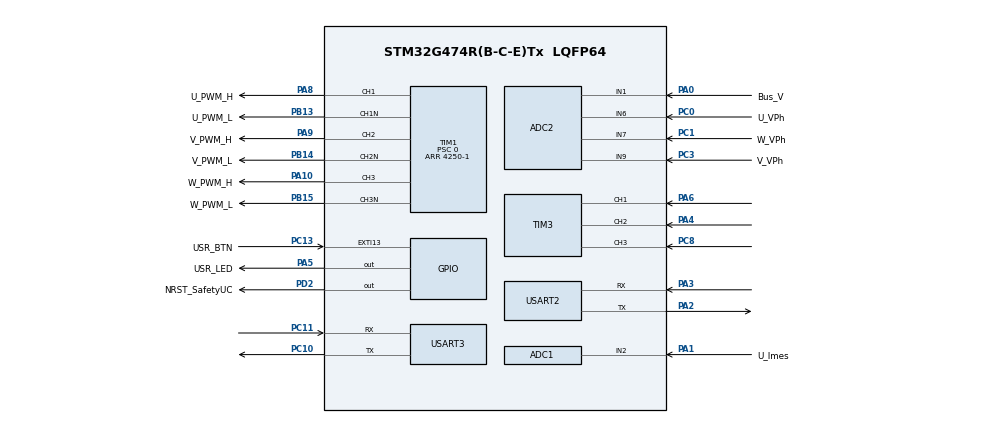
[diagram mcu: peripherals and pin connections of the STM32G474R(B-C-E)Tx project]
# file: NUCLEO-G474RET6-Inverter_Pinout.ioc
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ADC1.Channel-0\#ChannelRegularConversion=ADC_CHANNEL_2
ADC1.ContinuousConvMode=DISABLE
ADC1.DMAContinuousRequests=DISABLE
ADC1.ExternalTrigConv=ADC_EXTERNALTRIG_T1_TRGO
ADC1.NbrOfConversionFlag=1
ADC1.OffsetNumber-0\#ChannelRegularConversion=ADC_OFFSET_NONE
ADC1.OversamplingMode=DISABLE
ADC1.Rank-0\#ChannelRegularConversion=1
ADC1.SamplingTime-0\#ChannelRegularConversion=ADC_SAMPLETIME_2CYCLES_5
ADC1.master=1
ADC2.Channel-0\#ChannelRegularConversion=ADC_CHANNEL_6
ADC2.NbrOfConversionFlag=1
ADC2.OffsetNumber-0\#ChannelRegularConversion=ADC_OFFSET_NONE
ADC2.Rank-0\#ChannelRegularConversion=1
ADC2.SamplingTime-0\#ChannelRegularConversion=ADC_SAMPLETIME_2CYCLES_5
Dma.ADC1.0.Direction=DMA_PERIPH_TO_MEMORY
Dma.ADC1.0.EventEnable=DISABLE
Dma.ADC1.0.Instance=DMA1_Channel1
Dma.ADC1.0.MemDataAlignment=DMA_MDATAALIGN_HALFWORD
Dma.ADC1.0.MemInc=DMA_MINC_ENABLE
Dma.ADC1.0.Mode=DMA_NORMAL
Dma.ADC1.0.PeriphDataAlignment=DMA_PDATAALIGN_HALFWORD
Dma.ADC1.0.PeriphInc=DMA_PINC_DISABLE
Dma.ADC1.0.Polarity=HAL_DMAMUX_REQ_GEN_RISING
Dma.ADC1.0.Priority=DMA_PRIORITY_LOW
Dma.ADC1.0.RequestNumber=1
Dma.ADC1.0.SignalID=NONE
Dma.ADC1.0.SyncEnable=DISABLE
Dma.ADC1.0.SyncPolarity=HAL_DMAMUX_SYNC_NO_EVENT
Dma.ADC1.0.SyncRequestNumber=1
Dma.ADC1.0.SyncSignalID=NONE
Dma.Request0=ADC1
Mcu.Family=STM32G4
Mcu.Name=STM32G474R(B-C-E)Tx
Mcu.Package=LQFP64
NVIC.ADC1_2_IRQn=true\:0\:0\:false\:false\:true\:true\:true\:true
NVIC.DMA1_Channel1_IRQn=true\:0\:0\:false\:false\:true\:false\:true\:true
NVIC.EXTI15_10_IRQn=true\:0\:0\:false\:false\:true\:true\:true\:true
NVIC.PriorityGroup=NVIC_PRIORITYGROUP_4
NVIC.TIM1_TRG_COM_TIM17_IRQn=true\:0\:0\:false\:false\:true\:true\:true\:true
NVIC.TIM2_IRQn=true\:0\:0\:false\:false\:true\:true\:true\:true
NVIC.TIM6_DAC_IRQn=true\:15\:0\:false\:false\:true\:false\:true\:true
NVIC.TimeBase=TIM6_DAC_IRQn
NVIC.TimeBaseIP=TIM6
NVIC.USART2_IRQn=true\:0\:0\:false\:false\:true\:true\:true\:true
NVIC.USART3_IRQn=true\:0\:0\:false\:false\:true\:true\:true\:true
PA0.GPIO_Label=Bus_V
PA0.Mode=IN1-Single-Ended
PA0.Signal=ADC2_IN1
PA1.GPIO_Label=U_Imes
PA1.Mode=IN2-Single-Ended
PA1.Signal=ADC1_IN2
PA10.GPIO_Label=W_PWM_H
PA10.Signal=S_TIM1_CH3
PA13.GPIO_Label=T_SWDIO
PA13.Mode=Trace_Asynchronous_SW
PA13.Signal=SYS_JTMS-SWDIO
PA14.GPIO_Label=T_SWCLK
PA14.Mode=Trace_Asynchronous_SW
PA14.Signal=SYS_JTCK-SWCLK
PA2.Mode=Asynchronous
PA2.Signal=USART2_TX
PA3.Mode=Asynchronous
PA3.Signal=USART2_RX
PA4.Signal=S_TIM3_CH2
PA5.GPIO_Label=USR_LED
PA5.Signal=GPIO_Output
PA6.Signal=S_TIM3_CH1
PA8.GPIO_Label=U_PWM_H
PA8.Signal=S_TIM1_CH1
PA9.GPIO_Label=V_PWM_H
PA9.Signal=S_TIM1_CH2
PB0.Signal=ADC1_IN15
PB1.Signal=ADC1_IN12
PB13.GPIO_Label=U_PWM_L
PB13.Mode=PWM Generation1 CH1 CH1N
PB13.Signal=TIM1_CH1N
PB14.GPIO_Label=V_PWM_L
PB14.Mode=PWM Generation2 CH2 CH2N
PB14.Signal=TIM1_CH2N
PB15.GPIO_Label=W_PWM_L
PB15.Mode=PWM Generation3 CH3 CH3N
PB15.Signal=TIM1_CH3N
PB3.GPIO_Label=T_SWO
PB3.Mode=Trace_Asynchronous_SW
PB3.Signal=SYS_JTDO-SWO
PC0.GPIO_Label=U_VPh
PC0.Mode=IN6-Single-Ended
PC0.Signal=ADC2_IN6
PC1.GPIO_Label=W_VPh
PC1.Mode=IN7-Single-Ended
PC1.Signal=ADC2_IN7
PC10.Mode=Asynchronous
PC10.Signal=USART3_TX
PC11.Mode=Asynchronous
PC11.Signal=USART3_RX
PC13.GPIO_Label=USR_BTN
PC13.Signal=GPXTI13
PC14-OSC32_IN.Mode=LSE-External-Oscillator
PC14-OSC32_IN.Signal=RCC_OSC32_IN
PC15-OSC32_OUT.Mode=LSE-External-Oscillator
PC15-OSC32_OUT.Signal=RCC_OSC32_OUT
PC2.GPIO_Label=Bus_Imes
PC2.Signal=ADC1_IN8
PC3.GPIO_Label=V_VPh
PC3.Mode=IN9-Single-Ended
PC3.Signal=ADC2_IN9
PC8.Signal=S_TIM3_CH3
PD2.GPIO_Label=NRST_SafetyUC
PD2.Signal=GPIO_Output
PF0-OSC_IN.Mode=HSE-External-Oscillator
PF0-OSC_IN.Signal=RCC_OSC_IN
PF1-OSC_OUT.Mode=HSE-External-Oscillator
PF1-OSC_OUT.Signal=RCC_OSC_OUT
ProjectManager.HeapSize=0x200
ProjectManager.StackSize=0x400
ProjectManager.TargetToolchain=STM32CubeIDE
RCC.ADC12Freq_Value=170000000
RCC.ADC345Freq_Value=170000000
RCC.AHBFreq_Value=170000000
RCC.APB1Freq_Value=170000000
RCC.APB1TimFreq_Value=170000000
RCC.APB2Freq_Value=170000000
RCC.APB2TimFreq_Value=170000000
RCC.CortexFreq_Value=170000000
RCC.EXTERNAL_CLOCK_VALUE=12288000
RCC.HCLKFreq_Value=170000000
RCC.HSE_VALUE=24000000
RCC.HSI48_VALUE=48000000
RCC.HSI_VALUE=16000000
RCC.PLLM=RCC_PLLM_DIV6
RCC.PLLN=85
RCC.PLLSourceVirtual=RCC_PLLSOURCE_HSE
RCC.RTCClockSelection=RCC_RTCCLKSOURCE_LSE
RCC.SYSCLKFreq_VALUE=170000000
RCC.SYSCLKSource=RCC_SYSCLKSOURCE_PLLCLK
RCC.USBFreq_Value=170000000
RCC.VCOOutputFreq_Value=340000000
SH.S_TIM1_CH1.0=TIM1_CH1,PWM Generation1 CH1 CH1N
SH.S_TIM1_CH2.0=TIM1_CH2,PWM Generation2 CH2 CH2N
SH.S_TIM1_CH3.0=TIM1_CH3,PWM Generation3 CH3 CH3N
SH.S_TIM3_CH1.0=TIM3_CH1,Xored_Inputs_Hall_Sensor_Interface
SH.S_TIM3_CH2.0=TIM3_CH2,Xored_Inputs_Hall_Sensor_Interface
SH.S_TIM3_CH3.0=TIM3_CH3,Xored_Inputs_Hall_Sensor_Interface
TIM1.AutoReloadPreload=TIM_AUTORELOAD_PRELOAD_ENABLE
TIM1.Channel-PWM\ Generation1\ CH1\ CH1N=TIM_CHANNEL_1
TIM1.Channel-PWM\ Generation2\ CH2\ CH2N=TIM_CHANNEL_2
TIM1.Channel-PWM\ Generation3\ CH3\ CH3N=TIM_CHANNEL_3
TIM1.CounterMode=TIM_COUNTERMODE_CENTERALIGNED1
TIM1.DeadTime=34
TIM1.PeriodNoDither=4250-1
TIM1.Prescaler=0
TIM1.PulseNoDither_1=3000
TIM1.PulseNoDither_2=5000
TIM1.TIM_MasterOutputTrigger=TIM_TRGO_UPDATE
TIM1.TIM_MasterSlaveMode=TIM_MASTERSLAVEMODE_ENABLE
TIM2.PeriodNoDither=3333-1
TIM2.Prescaler=170-1
USART2.VirtualMode-Asynchronous=VM_ASYNC
USART3.VirtualMode-Asynchronous=VM_ASYNC
VP_SYS_VS_DBSignals.Mode=DisableDeadBatterySignals
VP_SYS_VS_tim6.Mode=TIM6
VP_TIM2_VS_ClockSourceINT.Mode=Internal
board=NUCLEO-G474RE

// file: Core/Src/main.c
/* USER CODE BEGIN Header */
/**
 ******************************************************************************
 * @file           : main.c
 * @brief          : Main program body
 ******************************************************************************
 * @attention
 *
 * Copyright (c) 2023 STMicroelectronics.
 * All rights reserved.
 *
 * This software is licensed under terms that can be found in the LICENSE file
 * in the root directory of this software component.
 * If no LICENSE file comes with this software, it is provided AS-IS.
 *
 ******************************************************************************
 */
/* USER CODE END Header */

#include "main.h"
#include "adc.h"
#include "dma.h"
#include "tim.h"
#include "usart.h"
#include "gpio.h"

/* USER CODE BEGIN Includes */
#include "mylibs/shell.h"
#include <stdio.h>
#include <stdlib.h>
/* USER CODE END Includes */

/**
 * @file main.c
 * @brief Entry point of the application, containing the main loop and peripheral initializations.
 */

/** @brief Maximum PWM value, corresponding to TIM1->ARR. */
#define PWM_MAX_VAL 4250

/** @brief Rate of variation for PWM pulse adjustment. */
#define PWM_VARIATION_RATE 2

/** @brief Current sensor resolution in volts per ampere. */
#define ADC_CURRENT_RESOLUTION 0.05

/** @brief ADC supply voltage. */
#define ADC_VCC 3.3

/** @brief Maximum ADC digital value (12-bit resolution). */
#define ADC_MAX_VAL 4096

/** @brief Offset value for ADC measurements. */
#define ADC_OFFSET 2421

/** @brief Size of the ADC data buffer. */
#define ADC_BUFF_SIZE 1

/** @brief Current PWM speed value. */
int current_speed_PWM;

/** @brief Requested PWM speed value. */
int requested_speed_PWM;

/** @brief Buffer to store ADC data. */
uint32_t pData[ADC_BUFF_SIZE];

/** @brief Measured voltage from the ADC. */
static float U_Imes = 0;

/** @brief ADC voltage output. */
static float Uadc = 0;

/**
 * @brief Sends a character via UART (overrides default character transmission).
 * @param ch Character to send.
 * @return The sent character.
 */
int __io_putchar(int ch)
{
    HAL_UART_Transmit(&huart2, (uint8_t *)&ch, 1, HAL_MAX_DELAY);
    return ch;
}

/**
 * @brief Adjusts the PWM pulse for TIM1 channels.
 *
 * This function modifies the `current_speed_PWM` to gradually approach
 * `requested_speed_PWM` and sets the appropriate pulse widths for TIM1 channels.
 */
void set_PWM()
{
    if (requested_speed_PWM < current_speed_PWM)
    {
        current_speed_PWM -= 1;
        __HAL_TIM_SET_COMPARE(&htim1, TIM_CHANNEL_1, current_speed_PWM);
        __HAL_TIM_SET_COMPARE(&htim1, TIM_CHANNEL_2,
                               __HAL_TIM_GET_AUTORELOAD(&htim1) - current_speed_PWM);
    }
    else if (requested_speed_PWM > current_speed_PWM)
    {
        current_speed_PWM += 1;
        __HAL_TIM_SET_COMPARE(&htim1, TIM_CHANNEL_1, current_speed_PWM);
        __HAL_TIM_SET_COMPARE(&htim1, TIM_CHANNEL_2,
                               __HAL_TIM_GET_AUTORELOAD(&htim1) - current_speed_PWM);
    }
}

/**
 * @brief Sets the PWM duty cycle ratio for TIM1 channels.
 * @param ratio Duty cycle ratio (0.0 to 1.0).
 */
void set_PWM_ratio(double ratio)
{
    if (ratio > 0 && ratio < 1)
    {
        requested_speed_PWM = (int)(ratio * PWM_MAX_VAL);
    }
}

/**
 * @brief Sets a specific PWM pulse width for TIM1 channels.
 * @param speed Desired PWM pulse width (0 to PWM_MAX_VAL).
 */
void set_PWM_speed(int speed)
{
    if (speed > 0 && speed < PWM_MAX_VAL)
    {
        requested_speed_PWM = speed;
    }
}

/**
 * @brief Starts PWM on TIM1 channels.
 *
 * Initializes the PWM channels with a base speed corresponding to a 50% duty cycle.
 */
void start_PWM()
{
    HAL_TIM_PWM_Start(&htim1, TIM_CHANNEL_1);
    HAL_TIMEx_PWMN_Start(&htim1, TIM_CHANNEL_1);

    HAL_TIM_PWM_Start(&htim1, TIM_CHANNEL_2);
    HAL_TIMEx_PWMN_Start(&htim1, TIM_CHANNEL_2);

    current_speed_PWM = PWM_MAX_VAL / 2 + 1;
    set_PWM_ratio(0.5);
}

/**
 * @brief Stops PWM on TIM1 channels.
 */
void stop_PWM()
{
    HAL_TIM_PWM_Stop(&htim1, TIM_CHANNEL_1);
    HAL_TIMEx_PWMN_Stop(&htim1, TIM_CHANNEL_1);

    HAL_TIM_PWM_Stop(&htim1, TIM_CHANNEL_2);
    HAL_TIMEx_PWMN_Stop(&htim1, TIM_CHANNEL_2);
}

/**
 * @brief Resets the microcontroller.
 */
void reset_inverter()
{
    NVIC_SystemReset();
}

/**
 * @brief Reads and prints the measured current using the ADC.
 *
 * Converts the ADC value to a voltage and calculates the current based
 * on the sensor's resolution.
 */
void read_current()
{
    printf("\r\nRAW ADC value: %d\r\n", (int)(pData[0]));

    Uadc = ADC_VCC * ((int)(pData[0]) - ADC_OFFSET) / ADC_MAX_VAL;
    U_Imes = Uadc / ADC_CURRENT_RESOLUTION;

    printf("\r\nMeasured tension: %f V\r\n", Uadc);
    printf("\r\nMeasured current: %f A\r\n", U_Imes);
}

/**
 * @brief ADC conversion complete callback. Restarts DMA for continuous conversion.
 * @param hadc ADC handle.
 */
void HAL_ADC_ConvCpltCallback(ADC_HandleTypeDef *hadc)
{
    if (hadc->Instance == ADC1)
    {
        HAL_ADC_Start_DMA(hadc, pData, ADC_BUFF_SIZE);
    }
}

/**
 * @brief Main entry point of the application.
 *
 * Initializes peripherals, starts the PWM, and enters the infinite loop
 * where the shell command interface runs.
 * @retval int Always returns 0.
 */
int main(void)
{
    HAL_Init();
    SystemClock_Config();

    MX_GPIO_Init();
    MX_DMA_Init();
    MX_ADC2_Init();
    MX_ADC1_Init();
    MX_TIM1_Init();
    MX_TIM3_Init();
    MX_USART2_UART_Init();
    MX_USART3_UART_Init();
    MX_TIM2_Init();

    HAL_TIM_Base_Start_IT(&htim2);

    HAL_ADCEx_Calibration_Start(&hadc1, ADC_SINGLE_ENDED);
    HAL_ADC_Start_DMA(&hadc1, pData, ADC_BUFF_SIZE);

    start_PWM();
    Shell_Init();

    while (1)
    {
        Shell_Loop();
    }
}

/**
 * @brief Configures the system clock.
 */
void SystemClock_Config(void)
{
    // Clock configuration details omitted for brevity
}

/**
 * @brief Timer period elapsed callback. Updates PWM when TIM2 interrupt occurs.
 * @param htim Timer handle.
 */
void HAL_TIM_PeriodElapsedCallback(TIM_HandleTypeDef *htim)
{
    if (htim->Instance == TIM2)
    {
        set_PWM();
    }

    if (htim->Instance == TIM6)
    {
        HAL_IncTick();
    }
}

/**
 * @brief Error handler function.
 *
 * Called in case of an unrecoverable error.
 */
void Error_Handler(void)
{
    __disable_irq();
    while (1)
    {
    }
}

/**
 * @brief Assert failed callback.
 * @param file File where the assertion occurred.
 * @param line Line number of the assertion.
 */
void assert_failed(uint8_t *file, uint32_t line)
{
    printf("Wrong parameter value: file %s on line %d\r\n", file, line);
}
